# iostr911fa register map
Registers from a debugger description file.
Registers are 16-bit, access not given, no defined reset value unless marked. A register's access mark holds for its fields unless they carry their own. Addresses are absolute; registers are grouped by the start of their names; lines under a group give offsets from that group; [hi:lo] are bit positions; {n}, {i} and the like mark numbered series; 'fields as' and 'values as' point back to an identical list; <NAME> marks a mode.

## FMI
0x44000000 FMI_BBSR_BUF 32-bit
  [3:0] BBSIZE
0x44000004 FMI_NBBSR_BUF 32-bit
  [3:0] NBBSIZE
0x4400000C FMI_BBADR_BUF 32-bit
  [23:0] BBADDR
0x44000010 FMI_NBBADR_BUF 32-bit
  [23:0] NBBADDR
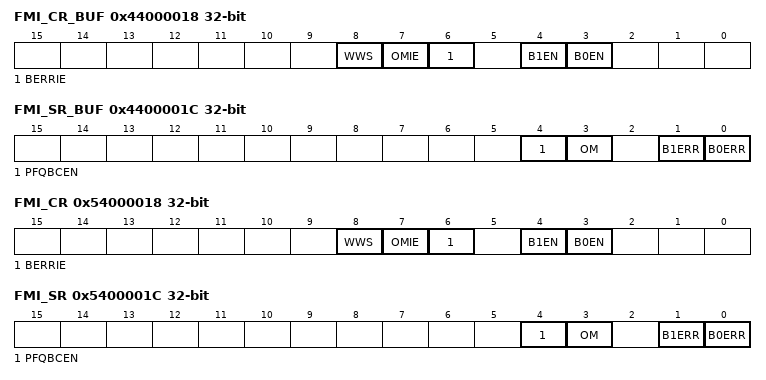
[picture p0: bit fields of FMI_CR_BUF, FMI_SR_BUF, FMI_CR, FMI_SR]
0x44000018 FMI_CR_BUF 32-bit
  [8] WWS, [7] OMIE, [6] BERRIE, [4] B1EN, [3] B0EN
0x4400001C FMI_SR_BUF 32-bit
  [4] PFQBCEN, [3] OM, [1] B1ERR, [0] B0ERR
0x44000020 FMI_BCE16ADDR_BUF 32-bit
  [23:0] BCE16ADDR
0x54000000 FMI_BBSR 32-bit
  [3:0] BBSIZE
0x54000004 FMI_NBBSR 32-bit
  [3:0] NBBSIZE
0x5400000C FMI_BBADR 32-bit
  [23:0] BBADDR
0x54000010 FMI_NBBADR 32-bit
  [23:0] NBBADDR
0x54000018 FMI_CR 32-bit
  [8] WWS, [7] OMIE, [6] BERRIE, [4] B1EN, [3] B0EN
0x5400001C FMI_SR 32-bit
  [4] PFQBCEN, [3] OM, [1] B1ERR, [0] B0ERR
0x54000020 FMI_BCE16ADDR 32-bit
  [23:0] BCE16ADDR

## GPIO0
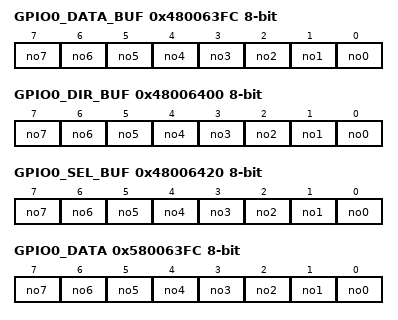
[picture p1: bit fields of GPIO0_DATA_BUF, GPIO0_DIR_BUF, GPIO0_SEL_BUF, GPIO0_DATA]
0x480063FC GPIO0_DATA_BUF 8-bit
  [n] no{n} (n=0..7)
0x48006400 GPIO0_DIR_BUF 8-bit
  [n] no{n} (n=0..7)
0x48006420 GPIO0_SEL_BUF 8-bit
  [n] no{n} (n=0..7)
0x580063FC GPIO0_DATA 8-bit
  [n] no{n} (n=0..7)
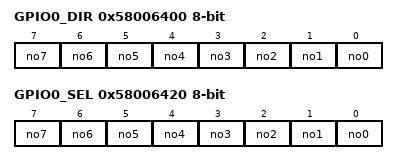
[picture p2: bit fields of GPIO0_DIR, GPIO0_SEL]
0x58006400 GPIO0_DIR 8-bit
  [n] no{n} (n=0..7)
0x58006420 GPIO0_SEL 8-bit
  [n] no{n} (n=0..7)

## GPIO1
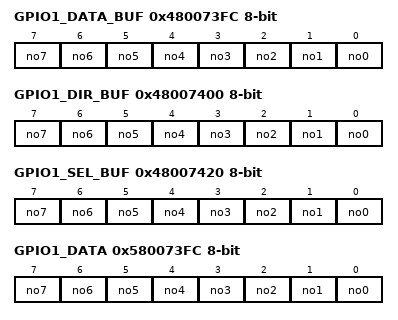
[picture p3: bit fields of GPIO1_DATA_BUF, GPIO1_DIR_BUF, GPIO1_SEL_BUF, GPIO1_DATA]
0x480073FC GPIO1_DATA_BUF 8-bit
  [n] no{n} (n=0..7)
0x48007400 GPIO1_DIR_BUF 8-bit
  [n] no{n} (n=0..7)
0x48007420 GPIO1_SEL_BUF 8-bit
  [n] no{n} (n=0..7)
0x580073FC GPIO1_DATA 8-bit
  [n] no{n} (n=0..7)
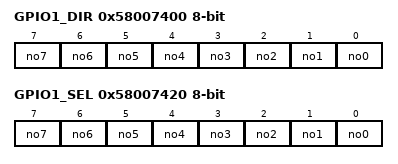
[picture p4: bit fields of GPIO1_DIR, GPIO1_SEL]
0x58007400 GPIO1_DIR 8-bit
  [n] no{n} (n=0..7)
0x58007420 GPIO1_SEL 8-bit
  [n] no{n} (n=0..7)

## GPIO2
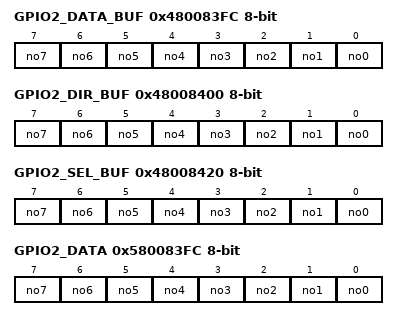
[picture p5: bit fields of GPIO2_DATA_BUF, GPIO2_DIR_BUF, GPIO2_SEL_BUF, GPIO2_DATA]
0x480083FC GPIO2_DATA_BUF 8-bit
  [n] no{n} (n=0..7)
0x48008400 GPIO2_DIR_BUF 8-bit
  [n] no{n} (n=0..7)
0x48008420 GPIO2_SEL_BUF 8-bit
  [n] no{n} (n=0..7)
0x580083FC GPIO2_DATA 8-bit
  [n] no{n} (n=0..7)
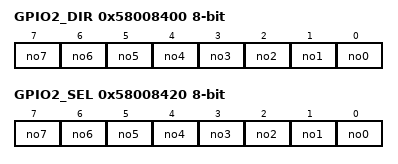
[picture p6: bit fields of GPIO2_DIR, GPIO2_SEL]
0x58008400 GPIO2_DIR 8-bit
  [n] no{n} (n=0..7)
0x58008420 GPIO2_SEL 8-bit
  [n] no{n} (n=0..7)

## GPIO3
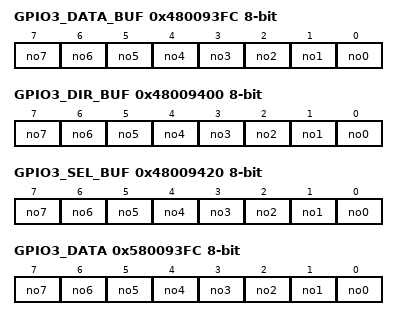
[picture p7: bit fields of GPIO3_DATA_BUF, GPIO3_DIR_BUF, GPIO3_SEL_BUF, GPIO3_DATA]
0x480093FC GPIO3_DATA_BUF 8-bit
  [n] no{n} (n=0..7)
0x48009400 GPIO3_DIR_BUF 8-bit
  [n] no{n} (n=0..7)
0x48009420 GPIO3_SEL_BUF 8-bit
  [n] no{n} (n=0..7)
0x580093FC GPIO3_DATA 8-bit
  [n] no{n} (n=0..7)
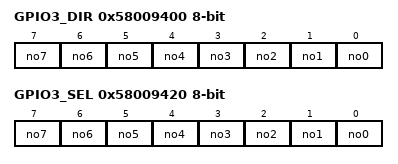
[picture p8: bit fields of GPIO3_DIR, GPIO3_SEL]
0x58009400 GPIO3_DIR 8-bit
  [n] no{n} (n=0..7)
0x58009420 GPIO3_SEL 8-bit
  [n] no{n} (n=0..7)

## GPIO4
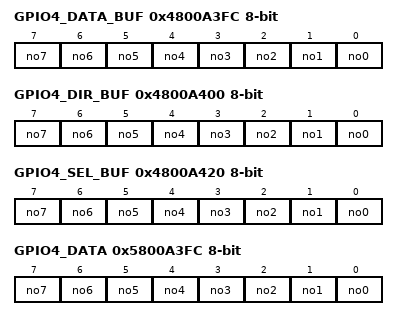
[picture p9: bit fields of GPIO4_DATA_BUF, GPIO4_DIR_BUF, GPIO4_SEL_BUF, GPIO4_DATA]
0x4800A3FC GPIO4_DATA_BUF 8-bit
  [n] no{n} (n=0..7)
0x4800A400 GPIO4_DIR_BUF 8-bit
  [n] no{n} (n=0..7)
0x4800A420 GPIO4_SEL_BUF 8-bit
  [n] no{n} (n=0..7)
0x5800A3FC GPIO4_DATA 8-bit
  [n] no{n} (n=0..7)
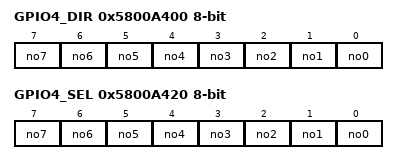
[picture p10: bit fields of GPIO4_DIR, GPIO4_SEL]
0x5800A400 GPIO4_DIR 8-bit
  [n] no{n} (n=0..7)
0x5800A420 GPIO4_SEL 8-bit
  [n] no{n} (n=0..7)

## GPIO5
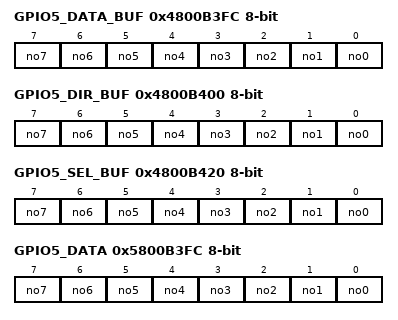
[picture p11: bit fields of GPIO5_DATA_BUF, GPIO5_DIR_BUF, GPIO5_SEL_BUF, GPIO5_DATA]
0x4800B3FC GPIO5_DATA_BUF 8-bit
  [n] no{n} (n=0..7)
0x4800B400 GPIO5_DIR_BUF 8-bit
  [n] no{n} (n=0..7)
0x4800B420 GPIO5_SEL_BUF 8-bit
  [n] no{n} (n=0..7)
0x5800B3FC GPIO5_DATA 8-bit
  [n] no{n} (n=0..7)
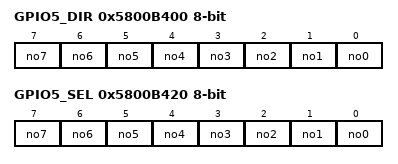
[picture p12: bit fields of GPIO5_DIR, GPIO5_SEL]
0x5800B400 GPIO5_DIR 8-bit
  [n] no{n} (n=0..7)
0x5800B420 GPIO5_SEL 8-bit
  [n] no{n} (n=0..7)

## GPIO6
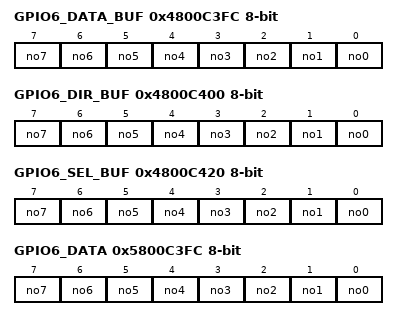
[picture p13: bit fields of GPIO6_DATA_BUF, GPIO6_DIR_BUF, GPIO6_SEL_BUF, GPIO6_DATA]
0x4800C3FC GPIO6_DATA_BUF 8-bit
  [n] no{n} (n=0..7)
0x4800C400 GPIO6_DIR_BUF 8-bit
  [n] no{n} (n=0..7)
0x4800C420 GPIO6_SEL_BUF 8-bit
  [n] no{n} (n=0..7)
0x5800C3FC GPIO6_DATA 8-bit
  [n] no{n} (n=0..7)
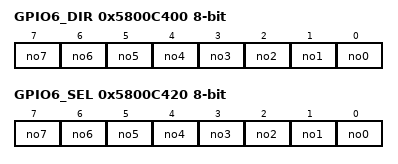
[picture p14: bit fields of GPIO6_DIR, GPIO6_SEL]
0x5800C400 GPIO6_DIR 8-bit
  [n] no{n} (n=0..7)
0x5800C420 GPIO6_SEL 8-bit
  [n] no{n} (n=0..7)
